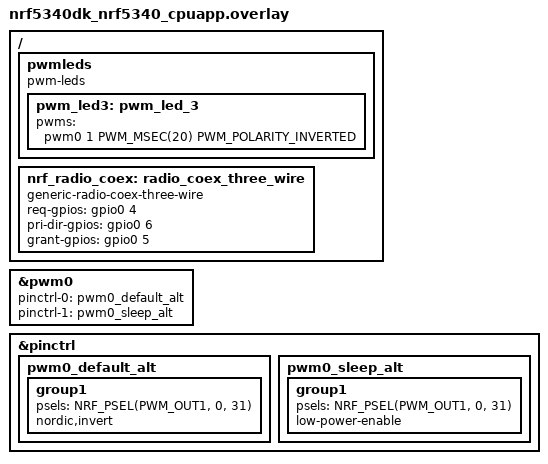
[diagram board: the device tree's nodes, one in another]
/*
 * Copyright (c) 2020-2022 Nordic Semiconductor ASA
 *
 * SPDX-License-Identifier: LicenseRef-Nordic-5-Clause
 */

/ {
	pwmleds {
		compatible = "pwm-leds";
		pwm_led3: pwm_led_3 {
			pwms = <&pwm0 1 PWM_MSEC(20) PWM_POLARITY_INVERTED>;
		};
	};
	nrf_radio_coex: radio_coex_three_wire {
		status = "okay";
		compatible = "generic-radio-coex-three-wire";
		req-gpios =     <&gpio0 4 (GPIO_ACTIVE_HIGH)>;
		pri-dir-gpios = <&gpio0 6 (GPIO_ACTIVE_HIGH)>;
		grant-gpios =   <&gpio0 5 (GPIO_ACTIVE_HIGH | GPIO_PULL_UP)>;
	};

};

&pwm0 {
	pinctrl-0 = <&pwm0_default_alt>;
	pinctrl-1 = <&pwm0_sleep_alt>;
	pinctrl-names = "default", "sleep";
};

&pinctrl {
	pwm0_default_alt: pwm0_default_alt {
		group1 {
			psels = <NRF_PSEL(PWM_OUT1, 0, 31)>;
			nordic,invert;
		};
	};

	pwm0_sleep_alt: pwm0_sleep_alt {
		group1 {
			psels = <NRF_PSEL(PWM_OUT1, 0, 31)>;
			low-power-enable;
		};
	};

};
